# STM32WL5x_CM4 register map
File version: 1.9
CPU: CM4 r0p1, little endian, MPU, FPU, 4 interrupt priority bits
Registers are 32-bit, read-write, reset 0x0 unless marked. A register's access mark holds for its fields unless they carry their own. Offsets are from the block's base; [hi:lo] are bit positions; {n}, {i} and the like mark numbered series; 'fields as' and 'values as' point back to an identical list.

## DMAMUX — DMA request multiplexer
Base 0x40020800
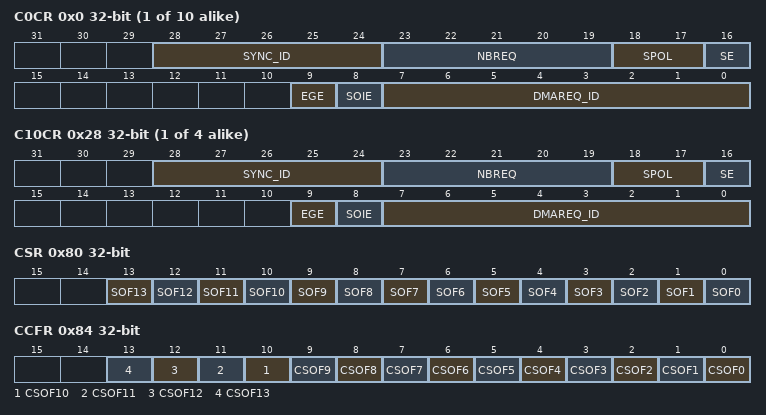
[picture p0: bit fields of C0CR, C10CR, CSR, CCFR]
{0x0+4i} C{i}CR (i=0..9) — request line multiplexer channel x configuration register
  [28:24] SYNC_ID — Synchronization identification
  [23:19] NBREQ — Number of DMA requests minus 1 to forward
  [18:17] SPOL — Synchronization polarity
  [16] SE — Synchronization enable
  [9] EGE — Event generation enable
  [8] SOIE — Synchronization overrun interrupt enable
  [7:0] DMAREQ_ID — DMA request identification
{0x0+4i} C{i}CR (i=10..13)
  [28:24] SYNC_ID, [23:19] NBREQ, [18:17] SPOL, [16] SE, [9] EGE, [8] SOIE, [7:0] DMAREQ_ID
0x80 CSR ro — request line multiplexer interrupt channel status register
  [13] SOF13 — Synchronization overrun event flag
  [n] SOF{n} (n=0..12)
0x84 CCFR wo — request line multiplexer interrupt channel clear flag register
  [n] CSOF{n} (n=0..13)
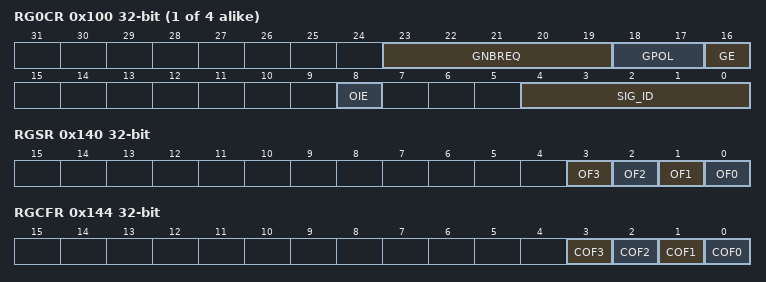
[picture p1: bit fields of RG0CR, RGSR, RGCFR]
{0x100+4i} RG{i}CR (i=0..3) — request generator channel x configuration register
  [23:19] GNBREQ — Number of DMA requests to be generated (minus 1)
  [18:17] GPOL — DMA request generator trigger polarity
  [16] GE — DMA request generator channel x enable
  [8] OIE — Trigger overrun interrupt enable
  [4:0] SIG_ID — Signal identification
0x140 RGSR ro — request generator interrupt status register
  [3] OF3 — Trigger overrun event flag
  [2] OF2
  [1] OF1
  [0] OF0
0x144 RGCFR wo — request generator interrupt clear flag register
  [3] COF3 — Clear trigger overrun event flag
  [2] COF2
  [1] COF1
  [0] COF0

## EXTI — External interrupt/event controller
Base 0x58000800
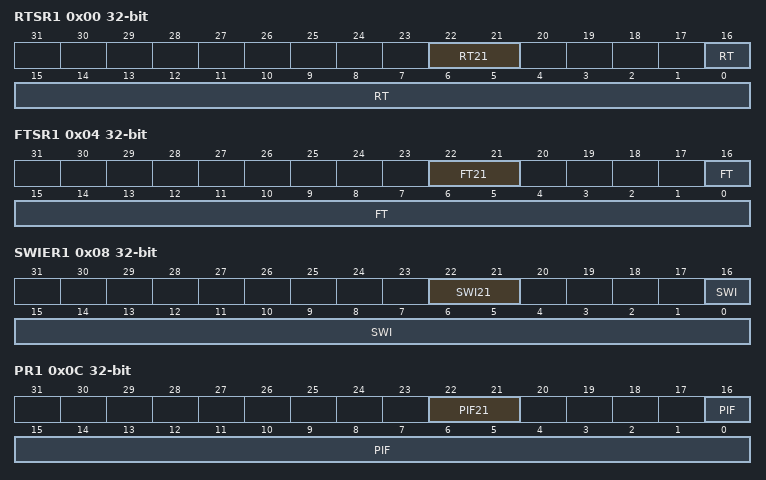
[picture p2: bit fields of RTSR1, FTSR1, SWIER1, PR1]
0x00 RTSR1 — rising trigger selection register
  [22:21] RT21 — Rising trigger event configuration bit of Configurable Event input
  [16:0] RT — Rising trigger event configuration bit of Configurable Event input
0x04 FTSR1 — falling trigger selection register
  [22:21] FT21 — Falling trigger event configuration bit of Configurable Event input
  [16:0] FT — Falling trigger event configuration bit of Configurable Event input
0x08 SWIER1 — software interrupt event register
  [22:21] SWI21 — Software interrupt on event
  [16:0] SWI — Software interrupt on event
0x0C PR1 — EXTI pending register
  [22:21] PIF21 — Configurable event inputs Pending bit
  [16:0] PIF — Configurable event inputs Pending bit
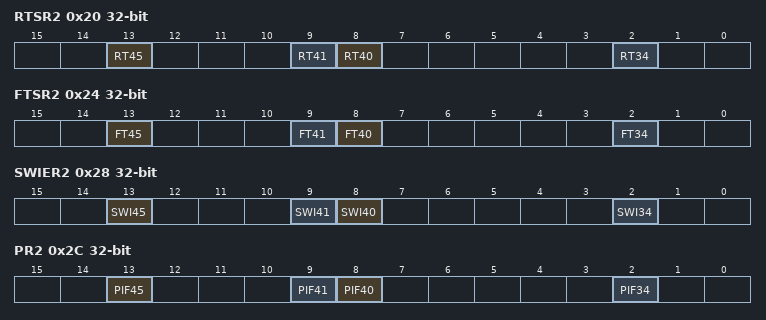
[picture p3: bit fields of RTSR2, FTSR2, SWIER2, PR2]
0x20 RTSR2 — rising trigger selection register
  [13] RT45 — Rising trigger event configuration bit of Configurable Event input
  [9] RT41 — Rising trigger event configuration bit of Configurable Event input
  [8] RT40 — Rising trigger event configuration bit of Configurable Event input
  [2] RT34 — Rising trigger event configuration bit of Configurable Event input
0x24 FTSR2 — falling trigger selection register
  [13] FT45 — Falling trigger event configuration bit of Configurable Event input
  [9] FT41 — Falling trigger event configuration bit of Configurable Event input
  [8] FT40 — Falling trigger event configuration bit of Configurable Event input
  [2] FT34 — Falling trigger event configuration bit of Configurable Event input
0x28 SWIER2 — software interrupt event register
  [13] SWI45 — Software interrupt on event 45
  [9] SWI41 — Software interrupt on event
  [8] SWI40 — Software interrupt on event
  [2] SWI34 — Software interrupt on event
0x2C PR2 — pending register
  [13] PIF45 — Configurable event inputs 45 Pending bit.
  [9] PIF41 — Configurable event inputs 40_41 Pending bit.
  [8] PIF40 — Configurable event inputs 40_41 Pending bit.
  [2] PIF34 — Configurable event inputs 33 Pending bit.
0x80 C1IMR1 — interrupt mask register
  [31:0] IM — wakeup with interrupt Mask on event input
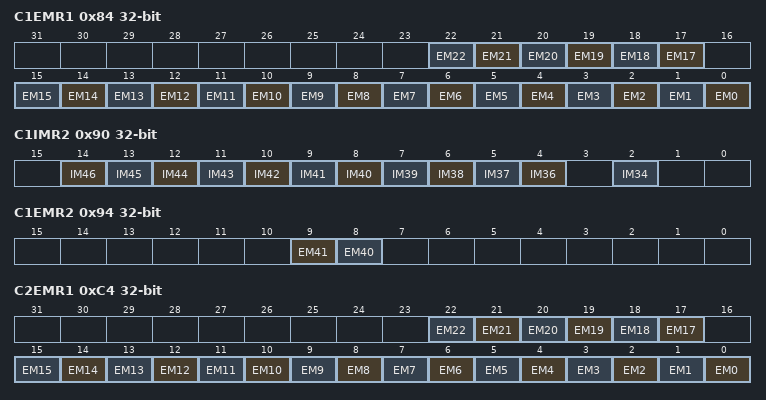
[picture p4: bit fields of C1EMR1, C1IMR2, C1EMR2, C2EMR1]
0x84 C1EMR1 — event mask register
  [n] EM{n} (n=17..22) — Wakeup with event generation Mask on Event input
  [n] EM{n} (n=0..15) — Wakeup with event generation Mask on Event input
0x90 C1IMR2 — wakeup with interrupt mask register
  [n-32] IM{n} (n=36..46) — wakeup with interrupt mask on event input
  [2] IM34 — wakeup with interrupt mask on event input
0x94 C1EMR2 — wakeup with event mask register
  [9] EM41 — Wakeup with event generation Mask on Event input
  [8] EM40 — Wakeup with event generation Mask on Event input
0xC0 C2IMR1 — interrupt mask register
  [31:0] IM — wakeup with interrupt Mask on Event input
0xC4 C2EMR1 — event mask register
  fields as C1EMR1
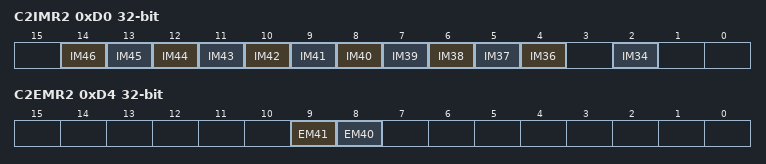
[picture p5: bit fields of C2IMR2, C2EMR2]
0xD0 C2IMR2 — wakeup with interrupt mask register
  fields as C1IMR2
0xD4 C2EMR2 — wakeup with event mask register
  fields as C1EMR2
